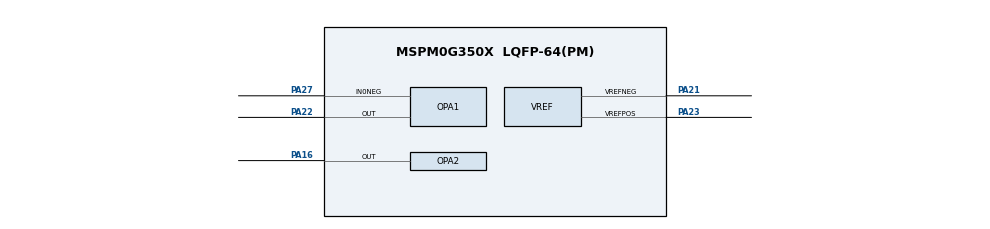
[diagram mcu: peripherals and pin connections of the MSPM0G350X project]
// @cliArgs --device "MSPM0G350X" --package "LQFP-64(PM)" --part "Default"
// @cliArgs --board /ti/boards/LP_MSPM0G3507 --rtos nortos

/**
 * Import the modules used in this configuration.
 */
const ADC12  = scripting.addModule("/ti/driverlib/ADC12", {}, false);
const ADC121 = ADC12.addInstance();
const Board  = scripting.addModule("/ti/driverlib/Board");
const COMP   = scripting.addModule("/ti/driverlib/COMP", {}, false);
const COMP1  = COMP.addInstance();
const OPA    = scripting.addModule("/ti/driverlib/OPA", {}, false);
const OPA1   = OPA.addInstance();
const OPA2   = OPA.addInstance();
const SYSCTL = scripting.addModule("/ti/driverlib/SYSCTL");
const VREF   = scripting.addModule("/ti/driverlib/VREF");

/**
 * Write custom configuration values to the imported modules.
 */
ADC121.$name                      = "ADC12_0";
ADC121.sampClkDiv                 = "DL_ADC12_CLOCK_DIVIDE_8";
ADC121.adcMem0chansel             = "DL_ADC12_INPUT_CHAN_13";
ADC121.sampleTime0                = "0.0625 ms";
ADC121.enabledInterrupts          = ["DL_ADC12_INTERRUPT_MEM0_RESULT_LOADED"];
ADC121.adcMem0avgen               = true;
ADC121.peripheral.$assign         = "ADC1";

Board.InitPriority8  = "/ti/driverlib/VREF";
Board.InitPriority10 = "/ti/driverlib/OPA";

COMP1.$name          = "COMP_0";
COMP1.hysteresis     = "DL_COMP_HYSTERESIS_20";
COMP1.vSource        = "DL_COMP_REF_SOURCE_VREF_DAC";
COMP1.terminalSelect = "DL_COMP_REF_TERMINAL_SELECT_NEG";
COMP1.controlSelect  = "DL_COMP_DAC_CONTROL_SW";
COMP1.setDACCode0    = 0x14;

OPA1.$name                        = "OPA_0";
OPA1.cfg0PSELChannel              = "DAC8_OUT";
OPA1.cfg0NSELChannel              = "IN0_NEG";
OPA1.cfg0OutputPin                = "ENABLED";
OPA1.advBW                        = "HIGH";
OPA1.peripheral.$assign           = "OPA0";
OPA1.peripheral.In0NegPin.$assign = "PA27";
OPA1.peripheral.OutPin.$assign    = "PA22";

OPA2.$name                     = "OPA_1";
OPA2.cfg0PSELChannel           = "RTOP";
OPA2.cfg0NSELChannel           = "RTAP";
OPA2.cfg0MSELChannel           = "GND";
OPA2.cfg0OutputPin             = "ENABLED";
OPA2.advBW                     = "HIGH";
OPA2.cfg0Chop                  = "ADC_AVERAGING";
OPA2.cfg0Gain                  = "N1_P2";
OPA2.peripheral.$assign        = "OPA1";
OPA2.peripheral.OutPin.$assign = "PA16";

VREF.basicVrefPins                 = "VREF+-";
VREF.basicIntVolt                  = "DL_VREF_BUFCONFIG_OUTPUT_2_5V";
VREF.checkVREFReady                = true;
VREF.advClockConfigEnable          = true;
VREF.advClkSrc                     = "DL_VREF_CLOCK_BUSCLK";
VREF.peripheral.$assign            = "VREF";
VREF.peripheral.vrefPosPin.$assign = "PA23";
VREF.peripheral.vrefNegPin.$assign = "PA21";

SYSCTL.forceDefaultClkConfig = true;
SYSCTL.clockTreeEn  = true;
